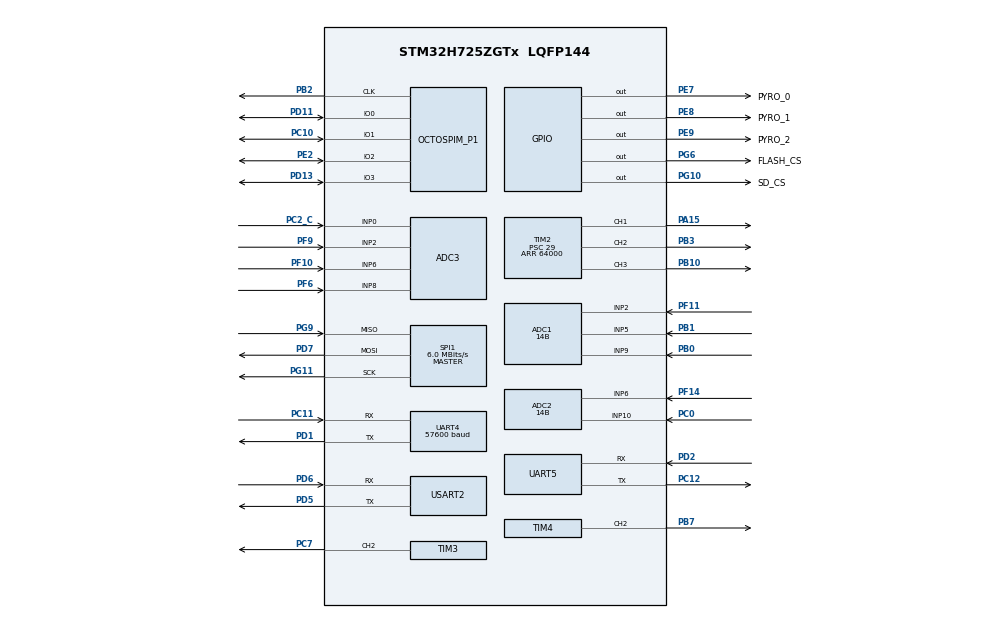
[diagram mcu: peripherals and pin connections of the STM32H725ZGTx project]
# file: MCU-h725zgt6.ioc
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ADC1.Channel-1\#ChannelRegularConversion=ADC_CHANNEL_2
ADC1.NbrOfConversion=1
ADC1.NbrOfConversionFlag=1
ADC1.OffsetNumber-1\#ChannelRegularConversion=ADC_OFFSET_NONE
ADC1.OffsetSignedSaturation-1\#ChannelRegularConversion=DISABLE
ADC1.Rank-1\#ChannelRegularConversion=1
ADC1.Resolution=ADC_RESOLUTION_14B
ADC1.SamplingTime-1\#ChannelRegularConversion=ADC_SAMPLETIME_810CYCLES_5
ADC1.master=1
ADC2.Channel-1\#ChannelRegularConversion=ADC_CHANNEL_6
ADC2.ClockPrescaler=ADC_CLOCK_ASYNC_DIV1
ADC2.ClockPrescalerADC3=ADC_CLOCK_SYNC_PCLK_DIV4
ADC2.ContinuousConvMode=DISABLE
ADC2.NbrOfConversion=1
ADC2.NbrOfConversionFlag=1
ADC2.OffsetNumber-1\#ChannelRegularConversion=ADC_OFFSET_NONE
ADC2.OffsetSignedSaturation-1\#ChannelRegularConversion=DISABLE
ADC2.OversamplingMode=DISABLE
ADC2.Rank-1\#ChannelRegularConversion=1
ADC2.Ratio=1
ADC2.Resolution=ADC_RESOLUTION_14B
ADC2.SamplingTime-1\#ChannelRegularConversion=ADC_SAMPLETIME_810CYCLES_5
ADC3.Channel-0\#ChannelRegularConversion=ADC_CHANNEL_0
ADC3.ClockPrescaler=ADC_CLOCK_ASYNC_DIV1
ADC3.ClockPrescalerADC3=ADC_CLOCK_SYNC_PCLK_DIV4
ADC3.ContinuousConvMode=DISABLE
ADC3.NbrOfConversion=1
ADC3.NbrOfConversionFlag=1
ADC3.OffsetNumber-0\#ChannelRegularConversion=ADC_OFFSET_NONE
ADC3.OffsetSign-0\#ChannelRegularConversion=ADC3_OFFSET_SIGN_NEGATIVE
ADC3.OversamplingMode=DISABLE
ADC3.Rank-0\#ChannelRegularConversion=1
ADC3.Ratio=ADC3_OVERSAMPLING_RATIO_2
ADC3.ResolutionADC3=ADC_RESOLUTION_12B
ADC3.SamplingTime-0\#ChannelRegularConversion=ADC3_SAMPLETIME_640CYCLES_5
CORTEX_M7.Enable_Spec=__NULL
CORTEX_M7.IsShareable_Spec=MPU_ACCESS_NOT_SHAREABLE
CORTEX_M7.default_mode_Activation=0
FATFS._MAX_SS=4096
FATFS._USE_LFN=1
Mcu.Family=STM32H7
Mcu.Name=STM32H725ZGTx
Mcu.Package=LQFP144
NVIC.ADC3_IRQn=true\:6\:0\:true\:false\:true\:true\:true\:true
NVIC.ADC_IRQn=true\:6\:0\:true\:false\:true\:true\:true\:true
NVIC.OCTOSPI1_IRQn=true\:5\:0\:true\:false\:true\:true\:true\:true
NVIC.PriorityGroup=NVIC_PRIORITYGROUP_4
NVIC.TIM1_UP_IRQn=true\:15\:0\:false\:false\:true\:false\:true\:true
NVIC.TIM2_IRQn=true\:0\:0\:false\:false\:true\:true\:true\:true
NVIC.TimeBase=TIM1_UP_IRQn
NVIC.TimeBaseIP=TIM1
NVIC.UART4_IRQn=true\:5\:0\:true\:false\:true\:true\:true\:true
NVIC.UART5_IRQn=true\:5\:0\:true\:false\:true\:true\:true\:true
NVIC.USART2_IRQn=true\:5\:0\:true\:false\:true\:true\:true\:true
OCTOSPI1.ClockPrescaler=2
OCTOSPI1.DeviceSize=24
PA13(JTMS/SWDIO).Mode=Serial_Wire
PA13(JTMS/SWDIO).Signal=DEBUG_JTMS-SWDIO
PA14(JTCK/SWCLK).Mode=Serial_Wire
PA14(JTCK/SWCLK).Signal=DEBUG_JTCK-SWCLK
PA15(JTDI).GPIO_ModeDefaultPP=GPIO_MODE_AF_PP
PA15(JTDI).Signal=S_TIM2_CH1_ETR
PB0.Signal=ADCx_INP9
PB1.Signal=ADCx_INP5
PB10.Signal=S_TIM2_CH3
PB2.Mode=O1_P1_CLK
PB2.Signal=OCTOSPIM_P1_CLK
PB3(JTDO/TRACESWO).Signal=S_TIM2_CH2
PB7.Signal=S_TIM4_CH2
PC0.Signal=ADCx_INP10
PC10.Mode=OCTOSPI1_IOL_Port1L
PC10.Signal=OCTOSPIM_P1_IO1
PC11.Mode=Asynchronous
PC11.Signal=UART4_RX
PC12.Mode=Asynchronous
PC12.Signal=UART5_TX
PC2_C.Mode=IN0-Single-Ended
PC2_C.Signal=ADC3_INP0
PC7.Signal=S_TIM3_CH2
PD1.Mode=Asynchronous
PD1.Signal=UART4_TX
PD11.Mode=OCTOSPI1_IOL_Port1L
PD11.Signal=OCTOSPIM_P1_IO0
PD13.Mode=OCTOSPI1_IOL_Port1L
PD13.Signal=OCTOSPIM_P1_IO3
PD2.Mode=Asynchronous
PD2.Signal=UART5_RX
PD5.Mode=Asynchronous
PD5.Signal=USART2_TX
PD6.Mode=Asynchronous
PD6.Signal=USART2_RX
PD7.Mode=Full_Duplex_Master
PD7.Signal=SPI1_MOSI
PE2.Mode=OCTOSPI1_IOL_Port1L
PE2.Signal=OCTOSPIM_P1_IO2
PE7.GPIO_Label=PYRO_0
PE7.GPIO_PuPd=GPIO_PULLDOWN
PE7.Signal=GPIO_Output
PE8.GPIO_Label=PYRO_1
PE8.GPIO_PuPd=GPIO_PULLDOWN
PE8.Signal=GPIO_Output
PE9.GPIO_Label=PYRO_2
PE9.GPIO_PuPd=GPIO_PULLDOWN
PE9.Signal=GPIO_Output
PF10.Mode=IN6-Single-Ended
PF10.Signal=ADC3_INP6
PF11.Mode=IN2-Single-Ended
PF11.Signal=ADC1_INP2
PF14.Mode=IN6-Single-Ended
PF14.Signal=ADC2_INP6
PF6.Mode=IN8-Single-Ended
PF6.Signal=ADC3_INP8
PF9.Mode=IN2-Single-Ended
PF9.Signal=ADC3_INP2
PG10.GPIO_Label=SD_CS
PG10.PinState=GPIO_PIN_SET
PG10.Signal=GPIO_Output
PG11.Mode=Full_Duplex_Master
PG11.Signal=SPI1_SCK
PG6.GPIO_Label=FLASH_CS
PG6.PinState=GPIO_PIN_SET
PG6.Signal=GPIO_Output
PG9.Mode=Full_Duplex_Master
PG9.Signal=SPI1_MISO
PH0-OSC_IN.Mode=HSE-External-Oscillator
PH0-OSC_IN.Signal=RCC_OSC_IN
PH1-OSC_OUT.Mode=HSE-External-Oscillator
PH1-OSC_OUT.Signal=RCC_OSC_OUT
ProjectManager.HeapSize=0x200
ProjectManager.StackSize=0x400
ProjectManager.TargetToolchain=Makefile
RCC.ADCFreq_Value=32000000
RCC.APB1Freq_Value=48000000
RCC.APB2Freq_Value=96000000
RCC.APB3Freq_Value=96000000
RCC.APB4Freq_Value=96000000
RCC.CortexFreq_Value=192000000
RCC.D2PPRE1=RCC_APB1_DIV2
RCC.DIVM1=1
RCC.DIVM2=1
RCC.DIVN1=24
RCC.DIVN2=32
RCC.DIVP1=1
RCC.DIVP2=8
RCC.HCLKFreq_Value=96000000
RCC.HPRE=RCC_HCLK_DIV2
RCC.HSE_VALUE=8000000
RCC.PLLFRACN=0
RCC.PLLSourceVirtual=RCC_PLLSOURCE_HSE
RCC.QSPICLockSelection=RCC_OSPICLKSOURCE_PLL
RCC.SYSCLKFreq_VALUE=192000000
RCC.SYSCLKSource=RCC_SYSCLKSOURCE_PLLCLK
RCC.SupplySource=PWR_LDO_SUPPLY
RCC.USBFreq_Value=96000000
SH.ADCx_INP10.0=ADC2_INP10,IN10-Single-Ended
SH.ADCx_INP5.0=ADC1_INP5,IN5-Single-Ended
SH.ADCx_INP9.0=ADC1_INP9,IN9-Single-Ended
SH.S_TIM2_CH1_ETR.0=TIM2_CH1,PWM Generation1 CH1
SH.S_TIM2_CH2.0=TIM2_CH2,PWM Generation2 CH2
SH.S_TIM2_CH3.0=TIM2_CH3,PWM Generation3 CH3
SH.S_TIM3_CH2.0=TIM3_CH2,PWM Generation2 CH2
SH.S_TIM4_CH2.0=TIM4_CH2,PWM Generation2 CH2
SPI1.BaudRatePrescaler=SPI_BAUDRATEPRESCALER_16
SPI1.CalculateBaudRate=6.0 MBits/s
SPI1.DataSize=SPI_DATASIZE_8BIT
SPI1.Direction=SPI_DIRECTION_2LINES
SPI1.Mode=SPI_MODE_MASTER
SPI1.VirtualType=VM_MASTER
TIM2.Channel-PWM\ Generation1\ CH1=TIM_CHANNEL_1
TIM2.Channel-PWM\ Generation2\ CH2=TIM_CHANNEL_2
TIM2.Channel-PWM\ Generation3\ CH3=TIM_CHANNEL_3
TIM2.OCMode_PWM-PWM\ Generation1\ CH1=TIM_OCMODE_PWM1
TIM2.Period=64000
TIM2.Prescaler=29
TIM3.Channel-PWM\ Generation2\ CH2=TIM_CHANNEL_2
TIM3.Period=64000
TIM3.Prescaler=29
TIM3.Pulse-PWM\ Generation2\ CH2=6400
TIM4.Channel-PWM\ Generation2\ CH2=TIM_CHANNEL_2
TIM4.Period=64000
TIM4.Prescaler=29
UART4.BaudRate=57600
USART2.VirtualMode-Asynchronous=VM_ASYNC
VP_FATFS_VS_Generic.Mode=User_defined
VP_MEMORYMAP_VS_MEMORYMAP.Mode=CurAppReg
VP_OCTOSPI1_VS_quad.Mode=quad_mode
VP_SYS_VS_tim1.Mode=TIM1
board=custom

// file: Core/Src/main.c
/* USER CODE BEGIN Header */
/**
  ******************************************************************************
  * @file           : main.c
  * @brief          : Main program body
  ******************************************************************************
  * @attention
  *
  * Copyright (c) 2024 STMicroelectronics.
  * All rights reserved.
  *
  * This software is licensed under terms that can be found in the LICENSE file
  * in the root directory of this software component.
  * If no LICENSE file comes with this software, it is provided AS-IS.
  *
  ******************************************************************************
  */
/* USER CODE END Header */
#include "main.h"
#include "fatfs.h"

/* USER CODE BEGIN Includes */
#include "port_layer.h"
#include "servo.h"
/* USER CODE END Includes */

ADC_HandleTypeDef hadc1;
ADC_HandleTypeDef hadc2;
ADC_HandleTypeDef hadc3;

OSPI_HandleTypeDef hospi1;

SPI_HandleTypeDef hspi1;

TIM_HandleTypeDef htim2;
TIM_HandleTypeDef htim3;
TIM_HandleTypeDef htim4;

UART_HandleTypeDef huart4;
UART_HandleTypeDef huart5;
UART_HandleTypeDef huart2;

void SystemClock_Config(void);
void PeriphCommonClock_Config(void);
static void MX_GPIO_Init(void);
static void MX_SPI1_Init(void);
static void MX_UART4_Init(void);
static void MX_UART5_Init(void);
static void MX_USART2_UART_Init(void);
static void MX_OCTOSPI1_Init(void);
static void MX_ADC2_Init(void);
static void MX_ADC3_Init(void);
static void MX_ADC1_Init(void);
static void MX_TIM2_Init(void);
static void MX_TIM4_Init(void);
static void MX_TIM3_Init(void);

/* USER CODE BEGIN 0 */
servo_t servo_1, servo_2;
/* USER CODE END 0 */

int main(void)
{

  /* MCU Configuration--------------------------------------------------------*/

  /* Reset of all peripherals, Initializes the Flash interface and the Systick. */
  HAL_Init();

  /* Configure the system clock */
  SystemClock_Config();

  /* Configure the peripherals common clocks */
  PeriphCommonClock_Config();

  /* Initialize all configured peripherals */
  MX_GPIO_Init();
  MX_SPI1_Init();
  MX_UART4_Init();
  MX_UART5_Init();
  MX_USART2_UART_Init();
  MX_FATFS_Init();
  MX_OCTOSPI1_Init();
  MX_ADC2_Init();
  MX_ADC3_Init();
  MX_ADC1_Init();
  MX_TIM2_Init();
  MX_TIM4_Init();
  MX_TIM3_Init();
  /* USER CODE BEGIN 2 */
  uint8_t tmp;
  while(HAL_TIMEOUT != HAL_UART_Receive(&state_uart, &tmp, 1, 10));

  if (port_init()) {
    HAL_UART_Transmit(&debug_uart, (uint8_t *) "Port initialized\r\n", 18, HAL_MAX_DELAY);
  } else {
    HAL_UART_Transmit(&debug_uart, (uint8_t *) "Port not initialized\r\n", 22, HAL_MAX_DELAY);
  }

  port_start();

  /* USER CODE END 2 */

  /* Infinite loop */
  while (1)
  {

  }
}

void SystemClock_Config(void)
{
  RCC_OscInitTypeDef RCC_OscInitStruct = {0};
  RCC_ClkInitTypeDef RCC_ClkInitStruct = {0};

  /** Supply configuration update enable
  */
  HAL_PWREx_ConfigSupply(PWR_LDO_SUPPLY);

  /** Configure the main internal regulator output voltage
  */
  __HAL_PWR_VOLTAGESCALING_CONFIG(PWR_REGULATOR_VOLTAGE_SCALE2);

  while(!__HAL_PWR_GET_FLAG(PWR_FLAG_VOSRDY)) {}

  /** Initializes the RCC Oscillators according to the specified parameters
  * in the RCC_OscInitTypeDef structure.
  */
  RCC_OscInitStruct.OscillatorType = RCC_OSCILLATORTYPE_HSE;
  RCC_OscInitStruct.HSEState = RCC_HSE_ON;
  RCC_OscInitStruct.PLL.PLLState = RCC_PLL_ON;
  RCC_OscInitStruct.PLL.PLLSource = RCC_PLLSOURCE_HSE;
  RCC_OscInitStruct.PLL.PLLM = 1;
  RCC_OscInitStruct.PLL.PLLN = 24;
  RCC_OscInitStruct.PLL.PLLP = 1;
  RCC_OscInitStruct.PLL.PLLQ = 2;
  RCC_OscInitStruct.PLL.PLLR = 2;
  RCC_OscInitStruct.PLL.PLLRGE = RCC_PLL1VCIRANGE_3;
  RCC_OscInitStruct.PLL.PLLVCOSEL = RCC_PLL1VCOWIDE;
  RCC_OscInitStruct.PLL.PLLFRACN = 0;
  if (HAL_RCC_OscConfig(&RCC_OscInitStruct) != HAL_OK)
  {
    Error_Handler();
  }

  /** Initializes the CPU, AHB and APB buses clocks
  */
  RCC_ClkInitStruct.ClockType = RCC_CLOCKTYPE_HCLK|RCC_CLOCKTYPE_SYSCLK
                              |RCC_CLOCKTYPE_PCLK1|RCC_CLOCKTYPE_PCLK2
                              |RCC_CLOCKTYPE_D3PCLK1|RCC_CLOCKTYPE_D1PCLK1;
  RCC_ClkInitStruct.SYSCLKSource = RCC_SYSCLKSOURCE_PLLCLK;
  RCC_ClkInitStruct.SYSCLKDivider = RCC_SYSCLK_DIV1;
  RCC_ClkInitStruct.AHBCLKDivider = RCC_HCLK_DIV2;
  RCC_ClkInitStruct.APB3CLKDivider = RCC_APB3_DIV1;
  RCC_ClkInitStruct.APB1CLKDivider = RCC_APB1_DIV2;
  RCC_ClkInitStruct.APB2CLKDivider = RCC_APB2_DIV1;
  RCC_ClkInitStruct.APB4CLKDivider = RCC_APB4_DIV1;

  if (HAL_RCC_ClockConfig(&RCC_ClkInitStruct, FLASH_LATENCY_1) != HAL_OK)
  {
    Error_Handler();
  }
}

void PeriphCommonClock_Config(void)
{
  RCC_PeriphCLKInitTypeDef PeriphClkInitStruct = {0};

  /** Initializes the peripherals clock
  */
  PeriphClkInitStruct.PeriphClockSelection = RCC_PERIPHCLK_ADC;
  PeriphClkInitStruct.PLL2.PLL2M = 1;
  PeriphClkInitStruct.PLL2.PLL2N = 32;
  PeriphClkInitStruct.PLL2.PLL2P = 8;
  PeriphClkInitStruct.PLL2.PLL2Q = 2;
  PeriphClkInitStruct.PLL2.PLL2R = 2;
  PeriphClkInitStruct.PLL2.PLL2RGE = RCC_PLL2VCIRANGE_3;
  PeriphClkInitStruct.PLL2.PLL2VCOSEL = RCC_PLL2VCOWIDE;
  PeriphClkInitStruct.PLL2.PLL2FRACN = 0;
  PeriphClkInitStruct.AdcClockSelection = RCC_ADCCLKSOURCE_PLL2;
  if (HAL_RCCEx_PeriphCLKConfig(&PeriphClkInitStruct) != HAL_OK)
  {
    Error_Handler();
  }
}

static void MX_ADC1_Init(void)
{

  ADC_MultiModeTypeDef multimode = {0};
  ADC_ChannelConfTypeDef sConfig = {0};

  /** Common config
  */
  hadc1.Instance = ADC1;
  hadc1.Init.ClockPrescaler = ADC_CLOCK_ASYNC_DIV1;
  hadc1.Init.Resolution = ADC_RESOLUTION_14B;
  hadc1.Init.ScanConvMode = ADC_SCAN_DISABLE;
  hadc1.Init.EOCSelection = ADC_EOC_SINGLE_CONV;
  hadc1.Init.LowPowerAutoWait = DISABLE;
  hadc1.Init.ContinuousConvMode = DISABLE;
  hadc1.Init.NbrOfConversion = 1;
  hadc1.Init.DiscontinuousConvMode = DISABLE;
  hadc1.Init.ExternalTrigConv = ADC_SOFTWARE_START;
  hadc1.Init.ExternalTrigConvEdge = ADC_EXTERNALTRIGCONVEDGE_NONE;
  hadc1.Init.ConversionDataManagement = ADC_CONVERSIONDATA_DR;
  hadc1.Init.Overrun = ADC_OVR_DATA_PRESERVED;
  hadc1.Init.LeftBitShift = ADC_LEFTBITSHIFT_NONE;
  hadc1.Init.OversamplingMode = DISABLE;
  hadc1.Init.Oversampling.Ratio = 1;
  if (HAL_ADC_Init(&hadc1) != HAL_OK)
  {
    Error_Handler();
  }

  /** Configure the ADC multi-mode
  */
  multimode.Mode = ADC_MODE_INDEPENDENT;
  if (HAL_ADCEx_MultiModeConfigChannel(&hadc1, &multimode) != HAL_OK)
  {
    Error_Handler();
  }

  /** Configure Regular Channel
  */
  sConfig.Channel = ADC_CHANNEL_2;
  sConfig.Rank = ADC_REGULAR_RANK_1;
  sConfig.SamplingTime = ADC_SAMPLETIME_810CYCLES_5;
  sConfig.SingleDiff = ADC_SINGLE_ENDED;
  sConfig.OffsetNumber = ADC_OFFSET_NONE;
  sConfig.Offset = 0;
  sConfig.OffsetSignedSaturation = DISABLE;
  if (HAL_ADC_ConfigChannel(&hadc1, &sConfig) != HAL_OK)
  {
    Error_Handler();
  }

}

static void MX_ADC2_Init(void)
{

  ADC_ChannelConfTypeDef sConfig = {0};

  /** Common config
  */
  hadc2.Instance = ADC2;
  hadc2.Init.ClockPrescaler = ADC_CLOCK_ASYNC_DIV1;
  hadc2.Init.Resolution = ADC_RESOLUTION_14B;
  hadc2.Init.ScanConvMode = ADC_SCAN_DISABLE;
  hadc2.Init.EOCSelection = ADC_EOC_SINGLE_CONV;
  hadc2.Init.LowPowerAutoWait = DISABLE;
  hadc2.Init.ContinuousConvMode = DISABLE;
  hadc2.Init.NbrOfConversion = 1;
  hadc2.Init.DiscontinuousConvMode = DISABLE;
  hadc2.Init.ExternalTrigConv = ADC_SOFTWARE_START;
  hadc2.Init.ExternalTrigConvEdge = ADC_EXTERNALTRIGCONVEDGE_NONE;
  hadc2.Init.ConversionDataManagement = ADC_CONVERSIONDATA_DR;
  hadc2.Init.Overrun = ADC_OVR_DATA_PRESERVED;
  hadc2.Init.LeftBitShift = ADC_LEFTBITSHIFT_NONE;
  hadc2.Init.OversamplingMode = DISABLE;
  hadc2.Init.Oversampling.Ratio = 1;
  if (HAL_ADC_Init(&hadc2) != HAL_OK)
  {
    Error_Handler();
  }

  /** Configure Regular Channel
  */
  sConfig.Channel = ADC_CHANNEL_6;
  sConfig.Rank = ADC_REGULAR_RANK_1;
  sConfig.SamplingTime = ADC_SAMPLETIME_810CYCLES_5;
  sConfig.SingleDiff = ADC_SINGLE_ENDED;
  sConfig.OffsetNumber = ADC_OFFSET_NONE;
  sConfig.Offset = 0;
  sConfig.OffsetSignedSaturation = DISABLE;
  if (HAL_ADC_ConfigChannel(&hadc2, &sConfig) != HAL_OK)
  {
    Error_Handler();
  }

}

static void MX_ADC3_Init(void)
{

  ADC_ChannelConfTypeDef sConfig = {0};

  /** Common config
  */
  hadc3.Instance = ADC3;
  hadc3.Init.ClockPrescaler = ADC_CLOCK_SYNC_PCLK_DIV4;
  hadc3.Init.Resolution = ADC_RESOLUTION_12B;
  hadc3.Init.DataAlign = ADC3_DATAALIGN_RIGHT;
  hadc3.Init.ScanConvMode = ADC_SCAN_DISABLE;
  hadc3.Init.EOCSelection = ADC_EOC_SINGLE_CONV;
  hadc3.Init.LowPowerAutoWait = DISABLE;
  hadc3.Init.ContinuousConvMode = DISABLE;
  hadc3.Init.NbrOfConversion = 1;
  hadc3.Init.DiscontinuousConvMode = DISABLE;
  hadc3.Init.ExternalTrigConv = ADC_SOFTWARE_START;
  hadc3.Init.ExternalTrigConvEdge = ADC_EXTERNALTRIGCONVEDGE_NONE;
  hadc3.Init.DMAContinuousRequests = DISABLE;
  hadc3.Init.SamplingMode = ADC_SAMPLING_MODE_NORMAL;
  hadc3.Init.ConversionDataManagement = ADC_CONVERSIONDATA_DR;
  hadc3.Init.Overrun = ADC_OVR_DATA_PRESERVED;
  hadc3.Init.LeftBitShift = ADC_LEFTBITSHIFT_NONE;
  hadc3.Init.OversamplingMode = DISABLE;
  hadc3.Init.Oversampling.Ratio = ADC3_OVERSAMPLING_RATIO_2;
  if (HAL_ADC_Init(&hadc3) != HAL_OK)
  {
    Error_Handler();
  }

  /** Configure Regular Channel
  */
  sConfig.Channel = ADC_CHANNEL_0;
  sConfig.Rank = ADC_REGULAR_RANK_1;
  sConfig.SamplingTime = ADC3_SAMPLETIME_640CYCLES_5;
  sConfig.SingleDiff = ADC_SINGLE_ENDED;
  sConfig.OffsetNumber = ADC_OFFSET_NONE;
  sConfig.Offset = 0;
  sConfig.OffsetSign = ADC3_OFFSET_SIGN_NEGATIVE;
  if (HAL_ADC_ConfigChannel(&hadc3, &sConfig) != HAL_OK)
  {
    Error_Handler();
  }

}

static void MX_OCTOSPI1_Init(void)
{

  OSPIM_CfgTypeDef sOspiManagerCfg = {0};

  /* OCTOSPI1 parameter configuration*/
  hospi1.Instance = OCTOSPI1;
  hospi1.Init.FifoThreshold = 1;
  hospi1.Init.DualQuad = HAL_OSPI_DUALQUAD_DISABLE;
  hospi1.Init.MemoryType = HAL_OSPI_MEMTYPE_MICRON;
  hospi1.Init.DeviceSize = 24;
  hospi1.Init.ChipSelectHighTime = 1;
  hospi1.Init.FreeRunningClock = HAL_OSPI_FREERUNCLK_DISABLE;
  hospi1.Init.ClockMode = HAL_OSPI_CLOCK_MODE_0;
  hospi1.Init.WrapSize = HAL_OSPI_WRAP_NOT_SUPPORTED;
  hospi1.Init.ClockPrescaler = 2;
  hospi1.Init.SampleShifting = HAL_OSPI_SAMPLE_SHIFTING_NONE;
  hospi1.Init.DelayHoldQuarterCycle = HAL_OSPI_DHQC_DISABLE;
  hospi1.Init.ChipSelectBoundary = 0;
  hospi1.Init.DelayBlockBypass = HAL_OSPI_DELAY_BLOCK_BYPASSED;
  hospi1.Init.MaxTran = 0;
  hospi1.Init.Refresh = 0;
  if (HAL_OSPI_Init(&hospi1) != HAL_OK)
  {
    Error_Handler();
  }
  sOspiManagerCfg.ClkPort = 1;
  sOspiManagerCfg.IOLowPort = HAL_OSPIM_IOPORT_1_LOW;
  if (HAL_OSPIM_Config(&hospi1, &sOspiManagerCfg, HAL_OSPI_TIMEOUT_DEFAULT_VALUE) != HAL_OK)
  {
    Error_Handler();
  }

}

static void MX_SPI1_Init(void)
{

  /* SPI1 parameter configuration*/
  hspi1.Instance = SPI1;
  hspi1.Init.Mode = SPI_MODE_MASTER;
  hspi1.Init.Direction = SPI_DIRECTION_2LINES;
  hspi1.Init.DataSize = SPI_DATASIZE_8BIT;
  hspi1.Init.CLKPolarity = SPI_POLARITY_LOW;
  hspi1.Init.CLKPhase = SPI_PHASE_1EDGE;
  hspi1.Init.NSS = SPI_NSS_SOFT;
  hspi1.Init.BaudRatePrescaler = SPI_BAUDRATEPRESCALER_16;
  hspi1.Init.FirstBit = SPI_FIRSTBIT_MSB;
  hspi1.Init.TIMode = SPI_TIMODE_DISABLE;
  hspi1.Init.CRCCalculation = SPI_CRCCALCULATION_DISABLE;
  hspi1.Init.CRCPolynomial = 0x0;
  hspi1.Init.NSSPMode = SPI_NSS_PULSE_ENABLE;
  hspi1.Init.NSSPolarity = SPI_NSS_POLARITY_LOW;
  hspi1.Init.FifoThreshold = SPI_FIFO_THRESHOLD_01DATA;
  hspi1.Init.TxCRCInitializationPattern = SPI_CRC_INITIALIZATION_ALL_ZERO_PATTERN;
  hspi1.Init.RxCRCInitializationPattern = SPI_CRC_INITIALIZATION_ALL_ZERO_PATTERN;
  hspi1.Init.MasterSSIdleness = SPI_MASTER_SS_IDLENESS_00CYCLE;
  hspi1.Init.MasterInterDataIdleness = SPI_MASTER_INTERDATA_IDLENESS_00CYCLE;
  hspi1.Init.MasterReceiverAutoSusp = SPI_MASTER_RX_AUTOSUSP_DISABLE;
  hspi1.Init.MasterKeepIOState = SPI_MASTER_KEEP_IO_STATE_DISABLE;
  hspi1.Init.IOSwap = SPI_IO_SWAP_DISABLE;
  if (HAL_SPI_Init(&hspi1) != HAL_OK)
  {
    Error_Handler();
  }

}

static void MX_TIM2_Init(void)
{

  TIM_MasterConfigTypeDef sMasterConfig = {0};
  TIM_OC_InitTypeDef sConfigOC = {0};

  htim2.Instance = TIM2;
  htim2.Init.Prescaler = 29;
  htim2.Init.CounterMode = TIM_COUNTERMODE_UP;
  htim2.Init.Period = 64000;
  htim2.Init.ClockDivision = TIM_CLOCKDIVISION_DIV1;
  htim2.Init.AutoReloadPreload = TIM_AUTORELOAD_PRELOAD_DISABLE;
  if (HAL_TIM_PWM_Init(&htim2) != HAL_OK)
  {
    Error_Handler();
  }
  sMasterConfig.MasterOutputTrigger = TIM_TRGO_RESET;
  sMasterConfig.MasterSlaveMode = TIM_MASTERSLAVEMODE_DISABLE;
  if (HAL_TIMEx_MasterConfigSynchronization(&htim2, &sMasterConfig) != HAL_OK)
  {
    Error_Handler();
  }
  sConfigOC.OCMode = TIM_OCMODE_PWM1;
  sConfigOC.Pulse = 0;
  sConfigOC.OCPolarity = TIM_OCPOLARITY_HIGH;
  sConfigOC.OCFastMode = TIM_OCFAST_DISABLE;
  if (HAL_TIM_PWM_ConfigChannel(&htim2, &sConfigOC, TIM_CHANNEL_1) != HAL_OK)
  {
    Error_Handler();
  }
  if (HAL_TIM_PWM_ConfigChannel(&htim2, &sConfigOC, TIM_CHANNEL_2) != HAL_OK)
  {
    Error_Handler();
  }
  if (HAL_TIM_PWM_ConfigChannel(&htim2, &sConfigOC, TIM_CHANNEL_3) != HAL_OK)
  {
    Error_Handler();
  }
  HAL_TIM_MspPostInit(&htim2);

}

static void MX_TIM3_Init(void)
{

  TIM_MasterConfigTypeDef sMasterConfig = {0};
  TIM_OC_InitTypeDef sConfigOC = {0};

  htim3.Instance = TIM3;
  htim3.Init.Prescaler = 29;
  htim3.Init.CounterMode = TIM_COUNTERMODE_UP;
  htim3.Init.Period = 64000;
  htim3.Init.ClockDivision = TIM_CLOCKDIVISION_DIV1;
  htim3.Init.AutoReloadPreload = TIM_AUTORELOAD_PRELOAD_DISABLE;
  if (HAL_TIM_PWM_Init(&htim3) != HAL_OK)
  {
    Error_Handler();
  }
  sMasterConfig.MasterOutputTrigger = TIM_TRGO_RESET;
  sMasterConfig.MasterSlaveMode = TIM_MASTERSLAVEMODE_DISABLE;
  if (HAL_TIMEx_MasterConfigSynchronization(&htim3, &sMasterConfig) != HAL_OK)
  {
    Error_Handler();
  }
  sConfigOC.OCMode = TIM_OCMODE_PWM1;
  sConfigOC.Pulse = 6400;
  sConfigOC.OCPolarity = TIM_OCPOLARITY_HIGH;
  sConfigOC.OCFastMode = TIM_OCFAST_DISABLE;
  if (HAL_TIM_PWM_ConfigChannel(&htim3, &sConfigOC, TIM_CHANNEL_2) != HAL_OK)
  {
    Error_Handler();
  }
  HAL_TIM_MspPostInit(&htim3);

}

static void MX_TIM4_Init(void)
{

  TIM_MasterConfigTypeDef sMasterConfig = {0};
  TIM_OC_InitTypeDef sConfigOC = {0};

  htim4.Instance = TIM4;
  htim4.Init.Prescaler = 29;
  htim4.Init.CounterMode = TIM_COUNTERMODE_UP;
  htim4.Init.Period = 64000;
  htim4.Init.ClockDivision = TIM_CLOCKDIVISION_DIV1;
  htim4.Init.AutoReloadPreload = TIM_AUTORELOAD_PRELOAD_DISABLE;
  if (HAL_TIM_PWM_Init(&htim4) != HAL_OK)
  {
    Error_Handler();
  }
  sMasterConfig.MasterOutputTrigger = TIM_TRGO_RESET;
  sMasterConfig.MasterSlaveMode = TIM_MASTERSLAVEMODE_DISABLE;
  if (HAL_TIMEx_MasterConfigSynchronization(&htim4, &sMasterConfig) != HAL_OK)
  {
    Error_Handler();
  }
  sConfigOC.OCMode = TIM_OCMODE_PWM1;
  sConfigOC.Pulse = 0;
  sConfigOC.OCPolarity = TIM_OCPOLARITY_HIGH;
  sConfigOC.OCFastMode = TIM_OCFAST_DISABLE;
  if (HAL_TIM_PWM_ConfigChannel(&htim4, &sConfigOC, TIM_CHANNEL_2) != HAL_OK)
  {
    Error_Handler();
  }
  HAL_TIM_MspPostInit(&htim4);

}

static void MX_UART4_Init(void)
{

  huart4.Instance = UART4;
  huart4.Init.BaudRate = 57600;
  huart4.Init.WordLength = UART_WORDLENGTH_8B;
  huart4.Init.StopBits = UART_STOPBITS_1;
  huart4.Init.Parity = UART_PARITY_NONE;
  huart4.Init.Mode = UART_MODE_TX_RX;
  huart4.Init.HwFlowCtl = UART_HWCONTROL_NONE;
  huart4.Init.OverSampling = UART_OVERSAMPLING_16;
  huart4.Init.OneBitSampling = UART_ONE_BIT_SAMPLE_DISABLE;
  huart4.Init.ClockPrescaler = UART_PRESCALER_DIV1;
  huart4.AdvancedInit.AdvFeatureInit = UART_ADVFEATURE_NO_INIT;
  if (HAL_UART_Init(&huart4) != HAL_OK)
  {
    Error_Handler();
  }
  if (HAL_UARTEx_SetTxFifoThreshold(&huart4, UART_TXFIFO_THRESHOLD_1_8) != HAL_OK)
  {
    Error_Handler();
  }
  if (HAL_UARTEx_SetRxFifoThreshold(&huart4, UART_RXFIFO_THRESHOLD_1_8) != HAL_OK)
  {
    Error_Handler();
  }
  if (HAL_UARTEx_DisableFifoMode(&huart4) != HAL_OK)
  {
    Error_Handler();
  }

}

static void MX_UART5_Init(void)
{

  huart5.Instance = UART5;
  huart5.Init.BaudRate = 115200;
  huart5.Init.WordLength = UART_WORDLENGTH_8B;
  huart5.Init.StopBits = UART_STOPBITS_1;
  huart5.Init.Parity = UART_PARITY_NONE;
  huart5.Init.Mode = UART_MODE_TX_RX;
  huart5.Init.HwFlowCtl = UART_HWCONTROL_NONE;
  huart5.Init.OverSampling = UART_OVERSAMPLING_16;
  huart5.Init.OneBitSampling = UART_ONE_BIT_SAMPLE_DISABLE;
  huart5.Init.ClockPrescaler = UART_PRESCALER_DIV1;
  huart5.AdvancedInit.AdvFeatureInit = UART_ADVFEATURE_NO_INIT;
  if (HAL_UART_Init(&huart5) != HAL_OK)
  {
    Error_Handler();
  }
  if (HAL_UARTEx_SetTxFifoThreshold(&huart5, UART_TXFIFO_THRESHOLD_1_8) != HAL_OK)
  {
    Error_Handler();
  }
  if (HAL_UARTEx_SetRxFifoThreshold(&huart5, UART_RXFIFO_THRESHOLD_1_8) != HAL_OK)
  {
    Error_Handler();
  }
  if (HAL_UARTEx_DisableFifoMode(&huart5) != HAL_OK)
  {
    Error_Handler();
  }

}

static void MX_USART2_UART_Init(void)
{

  huart2.Instance = USART2;
  huart2.Init.BaudRate = 115200;
  huart2.Init.WordLength = UART_WORDLENGTH_8B;
  huart2.Init.StopBits = UART_STOPBITS_1;
  huart2.Init.Parity = UART_PARITY_NONE;
  huart2.Init.Mode = UART_MODE_TX_RX;
  huart2.Init.HwFlowCtl = UART_HWCONTROL_NONE;
  huart2.Init.OverSampling = UART_OVERSAMPLING_16;
  huart2.Init.OneBitSampling = UART_ONE_BIT_SAMPLE_DISABLE;
  huart2.Init.ClockPrescaler = UART_PRESCALER_DIV1;
  huart2.AdvancedInit.AdvFeatureInit = UART_ADVFEATURE_NO_INIT;
  if (HAL_UART_Init(&huart2) != HAL_OK)
  {
    Error_Handler();
  }
  if (HAL_UARTEx_SetTxFifoThreshold(&huart2, UART_TXFIFO_THRESHOLD_1_8) != HAL_OK)
  {
    Error_Handler();
  }
  if (HAL_UARTEx_SetRxFifoThreshold(&huart2, UART_RXFIFO_THRESHOLD_1_8) != HAL_OK)
  {
    Error_Handler();
  }
  if (HAL_UARTEx_DisableFifoMode(&huart2) != HAL_OK)
  {
    Error_Handler();
  }

}

static void MX_GPIO_Init(void)
{
  GPIO_InitTypeDef GPIO_InitStruct = {0};

  /* GPIO Ports Clock Enable */
  __HAL_RCC_GPIOE_CLK_ENABLE();
  __HAL_RCC_GPIOF_CLK_ENABLE();
  __HAL_RCC_GPIOH_CLK_ENABLE();
  __HAL_RCC_GPIOC_CLK_ENABLE();
  __HAL_RCC_GPIOB_CLK_ENABLE();
  __HAL_RCC_GPIOD_CLK_ENABLE();
  __HAL_RCC_GPIOG_CLK_ENABLE();
  __HAL_RCC_GPIOA_CLK_ENABLE();

  /*Configure GPIO pin Output Level */
  HAL_GPIO_WritePin(GPIOE, PYRO_0_Pin|PYRO_1_Pin|PYRO_2_Pin, GPIO_PIN_RESET);

  /*Configure GPIO pin Output Level */
  HAL_GPIO_WritePin(GPIOG, FLASH_CS_Pin|SD_CS_Pin, GPIO_PIN_SET);

  /*Configure GPIO pins : PYRO_0_Pin PYRO_1_Pin PYRO_2_Pin */
  GPIO_InitStruct.Pin = PYRO_0_Pin|PYRO_1_Pin|PYRO_2_Pin;
  GPIO_InitStruct.Mode = GPIO_MODE_OUTPUT_PP;
  GPIO_InitStruct.Pull = GPIO_PULLDOWN;
  GPIO_InitStruct.Speed = GPIO_SPEED_FREQ_LOW;
  HAL_GPIO_Init(GPIOE, &GPIO_InitStruct);

  /*Configure GPIO pins : FLASH_CS_Pin SD_CS_Pin */
  GPIO_InitStruct.Pin = FLASH_CS_Pin|SD_CS_Pin;
  GPIO_InitStruct.Mode = GPIO_MODE_OUTPUT_PP;
  GPIO_InitStruct.Pull = GPIO_NOPULL;
  GPIO_InitStruct.Speed = GPIO_SPEED_FREQ_LOW;
  HAL_GPIO_Init(GPIOG, &GPIO_InitStruct);

}

void HAL_TIM_PeriodElapsedCallback(TIM_HandleTypeDef *htim)
{
  if (htim->Instance == TIM1) {
    HAL_IncTick();
  }
}

void Error_Handler(void)
{
  __disable_irq();
  while (1)
  {
  }
}
